# rl2_of_cba4_RL2_OF_CBA4_25000000h register map
Vendor: Texas Instruments
Peripheral module from a debugger description file (folder AM275x).
Registers are 32-bit, read-write, reset 0x0 unless marked. A register's access mark holds for its fields unless they carry their own. Offsets are as the file gives them; lines under a group give offsets from that group; [hi:lo] are bit positions; {n}, {i} and the like mark numbered series; 'fields as' and 'values as' point back to an identical list; <NAME> marks a mode.

## rl2_of_cba4
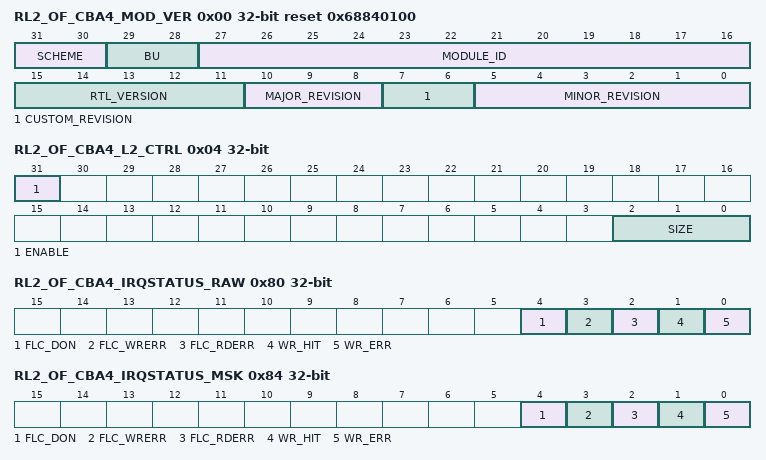
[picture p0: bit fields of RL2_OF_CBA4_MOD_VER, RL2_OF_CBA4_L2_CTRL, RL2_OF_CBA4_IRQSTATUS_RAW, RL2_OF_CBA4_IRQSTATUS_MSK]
0x00 RL2_OF_CBA4_MOD_VER ro reset 0x68840100 — The Module and Version Register identifies the module identifier and revision of the RL2 module.
  [31:30] SCHEME — Module Scheme
  [29:28] BU — Module Business Unit
  [27:16] MODULE_ID — RL2 module ID.
  [15:11] RTL_VERSION
  [10:8] MAJOR_REVISION
  [7:6] CUSTOM_REVISION
  [5:0] MINOR_REVISION
0x04 RL2_OF_CBA4_L2_CTRL — The control register defines the size of the remote cache data storage memory to use and whether the L2 is enabled.
  [31] ENABLE — The ~ienable field determines whether the L2 is enabled or not. Setting the enable from a 0 to 1 restarts the cache 0: Disabled 1: Enabled
  [2:0] SIZE — The ~isize field determines the size of the remote cache data storage memory that is currently active. This field can be change dynamically, but will cause the entire cache to be invalidated when inflight transactions have completed. Changing the ~isize while ~ienable is already a '1' will restart the cache. 0: 8KB 1: 16KB 2: 32KB 3: 64KB 4: 128KB 5: 256KB (Dual Mode) Note: Setting this field to an invalid value will result in the field being set to '0'. The remote address range registers must be setup correctly to ensure it has sufficient memory for the selected size.
0x08 RL2_OF_CBA4_L2_STS ro — The Status register displays the state of the RL2 module
  [31] OK_TO_GO — The ~iok_to_go status bit indicates the Tag/LRU Ram has been initialized and the cache is in an operable state.
0x10 RL2_OF_CBA4_L2_LO_LSW — The L2 Low address Least Significant word defines the least significant portion of the low cache address. The RL2 cache can cache a range of 1 to 16MB of cache as defined by L2_LO>=CachedRange<=L2_HI. This register is write protected when ~ienable is set.
  [31:11] ADDRESS_LO_LSW — The ~iaddress_lo_lsw defines the L2 low address[31:11] for the RL2 to cache. The remaining bits 10:0 are assumed to be zero.
0x14 RL2_OF_CBA4_L2_LO_MSW — The L2 Low address Most Significant word defines the most significant portion of the low cache address. The RL2 cache can cache a range of 1 to 16MB of cache as defined by L2_LO>=CachedRange<=L2_HI. This register is write protected when ~ienable is set.
  [15:0] ADDRESS_LO_MSW — The ~iaddress_lo_msw defines the L2 low address[ 47:32] for the RL2 to cache.
0x18 RL2_OF_CBA4_L2_HI — The L2 High address Least Significant word defines the least significant portion of the high cache address. The RL2 cache can cache a range of 1 to 16MB of cache as defined by L2_LO>=CachedRange<=L2_HI. This register is write protected when ~ienable is set.
  [31:11] ADDRESS_HI_LSW — The ~iaddress_hi_lsw defines the high address[31:11] for the RL2 to cache. The remaining bits 10:0 are assumed to be ones.
0x1C RL2_OF_CBA4_L2_HI_MSW — The L2 Hi address Most Significant word defines the most significant portion of the high cache address. The RL2 cache can cache a range of 1 to 16MB of cache as defined by L2_LO>=CachedRange<=L2_HI. This register is write protected when ~ienable is set.
  [15:0] ADDRESS_HI_MSW — The ~iaddress_lo_msw defines the L2 hi address[ 47:32] for the RL2 to cache.
0x20 RL2_OF_CBA4_REM_ADR — The REMote 'n' Address Least Significant word defines the least significant portion of the Remote address for remote cache data storage memory 0. The RL2 cache use up to three remote cache data storage memory ranges to place the L2 data within. The length of these ranges must be greater or equal to the size specified. This register is write protected when ~ienable is set.
  [31:11] ADR_LSW — The ~irem0_adr_lsw defines the LSW of the remote cache data storage memory address[31:11] range 'n' for the RL2 to use for the cache. The remaining bits 10:0 are assumed to be zero.
0x24 RL2_OF_CBA4_REM_ADR_MSW — The REMote 'n' Address Most Significant word defines the Most significant portion of the Remote address for remote cache data storage memory 0. The RL2 cache use up to three remote cache data storage memory ranges to place the L2 data within. The length of these ranges must be greater or equal to the size specified. This register is write protected when ~ienable is set.
  [15:0] ADR_MSW — The ~irem0_adr_lsw defines the LSW of the remote cache data storage memory address[47:32] range 'n' for the RL2 to use for the cache.
0x28 RL2_OF_CBA4_REM_LEN — The Remote 'n' length defines the amount of remote cache data storage memory in 64 byte aligned quanta used starting from the REMote 'n' Address. The RL2 consumes remote cache data storage memory ranges in numeric order. Range 0 is consumed prior to range 1, etc. This register is write protected when ~ienable is set.
  [18:6] LEN — The ~irem0_len field specifies the length of the remote cache data storage memory 'n' to use for the RL2 cache in 64 byte quanta, That is the number of bytes specified in the remote cache data storage memory range 'n' is (~irem0_len X 64). Note: Any value greater than 4096 assumes 4096
0x78 RL2_OF_CBA4_L2HC — The L2 HIT Counter register holds the number of L2 Hits to the Remote data storage memory.
  [31:0] HIT — The ~ihit Counts the number of hits to the L2 cache. Writing to this register will set the value written or restarting the cache will clear its contents. This field does not roll over, it will stop counting at all ones.
0x7C RL2_OF_CBA4_L2MC — The L2 MISS Counter register holds the number of L2 Misses to the Remote data storage memory.
  [31:0] MISS — The ~imiss Counts the number of misses to the L2 cache. Writing to this register will set the value written or restarting the cache will clear its contents. This field does not roll over, it will stop counting at all ones.
0x80 RL2_OF_CBA4_IRQSTATUS_RAW access not given — The Interrupt Raw Status Register holds the raw status of the FLC/RL2 status/error interrupts.
  [4] FLC_DON — The ~iflc_don bit indicates a FLC has completed the transfer to the FLC range. Write 1 to set the ~iflc_don status for diagnostic purposes. Writing a 0 has no effect. (access R/W1TS)
  [3] FLC_WRERR — The ~iflc_wrerr bit indicates a write error from FLC remote range has occurred and the FLC is logically disabled while this bit is a '1'. Write 1 to set the ~iflc_wrerr status for diagnostic purposes. Writing a 0 has no effect. (access R/W1TS)
  [2] FLC_RDERR — The ~iflc_rderr bit indicates a read error from FLC range has occurred and the FLC is logically disabled while this bit is a '1'. Write 1 to set the ~iflc_rderr status for diagnostic purposes. Writing a 0 has no effect. (access R/W1TS)
  [1] WR_HIT — The ~iwr_hit bit indicates a write to the cacheable range has occurred potentially causing a coherency issue and the RL2 is logically disabled while this bit is a '1'. Write 1 to set the ~iwr_hit status for diagnostic purposes. Writing a 0 has no effect. (access R/W1TS)
  [0] WR_ERR — The ~iwr_err bit indicates a write error has occurred to the remote cache data storage memory and the RL2 is logically disabled while this bit is a '1'. Write 1 to set the ~iwr_err status for diagnostic purposes. Writing a 0 has no effect. (access R/W1TS)
0x84 RL2_OF_CBA4_IRQSTATUS_MSK access not given — The Interrupt Masked Status Register holds the masked status for the FLC/RL2 status/error interrupts. Writing to this register will EOI the interrupt, that is if another interrupt is pending, a new pulse interrupt will be generated.
  [4] FLC_DON — The ~iflc_don bit indicates a FLC has completed the transfer to the FLC range. Write 1 to clear the ~iflc_don status after interrupt has been serviced (raw status gets cleared, i.e. even if not enabled). Writing a 0 has no effect to this field. (access R/W1TC)
  [3] FLC_WRERR — The ~iflc_wrerr bit indicates a write error from FLC range has occurred and the FLC is logically disabled while this bit is a '1'. Write 1 to clear the ~iflc_wrerr status after interrupt has been serviced (raw status gets cleared, i.e. even if not enabled). Writing a 0 has no effect to this field. (access R/W1TC)
  [2] FLC_RDERR — The ~iflc_rderr bit indicates a read error from FLC range has occurred and the FLC is logically disabled while this bit is a '1'. Write 1 to clear the ~iflc_rderr status after interrupt has been serviced (raw status gets cleared, i.e. even if not enabled). Writing a 0 has no effect to this field. (access R/W1TC)
  [1] WR_HIT — The ~iwr_hit bit indicates a write to the cacheable range has occurred potentially causing a coherency issue and the RL2 is logically disabled while this bit is a '1'. Write 1 to clear the ~iwr_hit status after interrupt has been serviced (raw status gets cleared, i.e. even if not enabled). Writing a 0 has no effect to this field. (access R/W1TC)
  [0] WR_ERR — The ~iwr_err bit indicates a write error has occurred to the remote cache data storage memory and the RL2 is logically disabled while this bit is a '1'. Write 1 to clear the ~iwr_err status after interrupt has been serviced (raw status gets cleared, i.e. even if not enabled). Writing a 0 has no effect to this field. (access R/W1TC)
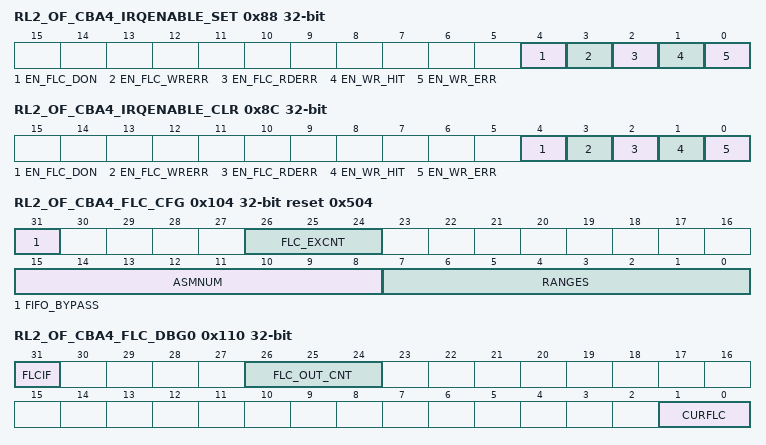
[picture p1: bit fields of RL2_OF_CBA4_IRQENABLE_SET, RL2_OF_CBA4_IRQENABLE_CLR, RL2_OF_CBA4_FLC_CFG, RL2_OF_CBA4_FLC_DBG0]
0x88 RL2_OF_CBA4_IRQENABLE_SET access not given — The Interrupt Enable Set Register holds the interrupt enable status of the FLC/RL2 status/error interrupts.
  [4] EN_FLC_DON — Interrupt Enable Set for ~ien_flc_don status bit. Writing a 1 will enable the interrupt, and set this bit as well as the corresponding Interrupt Enable Clear Register. Writing a 0 has no effect. (access R/W1TS)
  [3] EN_FLC_WRERR — Interrupt Enable Set for ~ien_flc_wrerr error bit. Writing a 1 will enable the interrupt, and set this bit as well as the corresponding Interrupt Enable Clear Register. Writing a 0 has no effect. (access R/W1TS)
  [2] EN_FLC_RDERR — Interrupt Enable Set for ~ien_flc_rderr error bit. Writing a 1 will enable the interrupt, and set this bit as well as the corresponding Interrupt Enable Clear Register. Writing a 0 has no effect. (access R/W1TS)
  [1] EN_WR_HIT — Interrupt Enable Set for ~iwr_hit error bit. Writing a 1 will enable the interrupt, and set this bit as well as the corresponding Interrupt Enable Clear Register. Writing a 0 has no effect. (access R/W1TS)
  [0] EN_WR_ERR — Interrupt Enable Set for ~iwr_err error bit. Writing a 1 will enable the interrupt, and set this bit as well as the corresponding Interrupt Enable Clear Register. Writing a 0 has no effect. (access R/W1TS)
0x8C RL2_OF_CBA4_IRQENABLE_CLR access not given — The Interrupt Enable Clear Register holds the interrupt enable status of the FLC/RL2 status/error interrupts.
  [4] EN_FLC_DON — Interrupt Enable Clear for ~iflc_don status bit. Writing a 1 will disable the interrupt, and clear this bit as well as the corresponding Interrupt Enable Set Register. Writing a 0 has no effect. (access R/W1TC)
  [3] EN_FLC_WRERR — Interrupt Enable Clear for ~iflc_wrerr error bit. Writing a 1 will disable the interrupt, and clear this bit as well as the corresponding Interrupt Enable Set Register. Writing a 0 has no effect. (access R/W1TC)
  [2] EN_FLC_RDERR — Interrupt Enable Clear for ~iflc_rderr error bit. Writing a 1 will disable the interrupt, and clear this bit as well as the corresponding Interrupt Enable Set Register. Writing a 0 has no effect. (access R/W1TC)
  [1] EN_WR_HIT — Interrupt Enable Clear for ~iwr_hit error bit. Writing a 1 will disable the interrupt, and clear this bit as well as the corresponding Interrupt Enable Set Register. Writing a 0 has no effect. (access R/W1TC)
  [0] EN_WR_ERR — Interrupt Enable Clear for ~iwr_err error bit. Writing a 1 will disable the interrupt, and clear this bit as well as the corresponding Interrupt Enable Set Register. Writing a 0 has no effect. (access R/W1TC)
0x104 RL2_OF_CBA4_FLC_CFG access per field reset 0x504 — The FLC Config Register contains the configuration values for the FLC.
  [31] FIFO_BYPASS rw — Setting this bit will cause the write to remote memory for a cache miss or FLC return to forces stalls on the read returns if any other data phase for a cache miss or FLC return is received. This can cause stalls on the write to force stalls on the read.
  [26:24] FLC_EXCNT rw — The number of extra requests the FLC can send. The maximum value is 4 anything greater will default to 4. This value + 1 is the number of Reassembly Buffers used for FLC so if cache misses needed to be supported this value should be set to 4 or lower. The number of cache misses that will be allowed to be outstanding while FLC is running will be 5 - (FLC_EXCNT + 1).
  [15:8] ASMNUM ro — Number of Reassembly Buffer supported
  [7:0] RANGES ro — Number of FLC ranges supported
0x108 RL2_OF_CBA4_FLC_STS ro — The FLC Status Register will indicate the state of the FLC completion.
  [3:0] CPYCMP — The ~icpycmp indicates which FLC range is complete. Each bit index indicates the FLC range is complete.
0x110 RL2_OF_CBA4_FLC_DBG0 ro — The FLC Debug 0 Register holds the debug state of the FLC.
  [31] FLCIF — The ~iflcif indicates a FLC operation is in flight.
  [26:24] FLC_OUT_CNT — The number of read requests the FLC operation has in flight.
  [1:0] CURFLC — The ~icurflc indicates which FLC range is in flight.
0x114 RL2_OF_CBA4_FLC_DBG1 ro — The FLC Debug 1 Register holds the debug address of the FLC.
  [31:0] FLCADR_LO — The ~iflcadr indicates the next FLC address to be processed if still in flight. That is all addresses less than this address have been transferred. This address is used for FLC hit when the particular FLC range is in flight. That is FLC_LO?>=FLCrange<~iflc_dbg1.flcadr would result in a hit. This address will match the last FLC transferred FLC_HI? when no FLC ranges are in flight.
0x118 RL2_OF_CBA4_FLC_DBG2 ro — The FLC Debug 2 Register holds the upper portion of the debug address of the FLC.
  [15:0] FLCADR_HI — The ~iflcadr indicates the next FLC address to be processed if still in flight. That is all addresses less than this address have been transferred. This address is used for FLC hit when the particular FLC range is in flight. That is FLC_LO?>=FLCrange<~iflc_dbg1.flcadr would result in a hit. This address will match the last FLC transferred FLC_HI? when no FLC ranges are in flight.
0x120 RL2_OF_CBA4_FLC_LO_j — The FLC Low 'n' address defines the FLC lo address for FLC range 0. The FLC range is defined by FLC_LO0>=FLCrange<FLC_HI0. This register is write protected when ~ifenable0 is set.
  [31:12] ADR_LO_LSW — The ~iadr0_lo defines the FLC low address[31:12] for the FLC to copy. The remaining bits 11:0 are assumed to be zero.
0x124 RL2_OF_CBA4_FLC_LO_MSW_j — The FLC Low 'n' address defines the FLC lo address for FLC range 0. The FLC range is defined by FLC_LO0>=FLCrange<FLC_HI0. This register is write protected when ~ifenable0 is set.
  [15:0] ADR_LO_MSW — The ~iadr0_lo defines the FLC low address[47:32] for the FLC to copy.
0x128 RL2_OF_CBA4_FLC_HI_j — The FLC High 'n' address defines the FLC high address for FLC range 0. The FLC range is defined by FLC_LO0>=FLCrange<FLC_HI0. This register is write protected when ~ifenable0 is set.
  [31:12] ADR_HI_LSW — The ~iadr0_hi defines the FLC high address[31:12] for the FLC to copy. The remaining bits 11:0 are assumed to be ones.
0x12C RL2_OF_CBA4_FLC_HI_MSW_j — The FLC High 'n' address defines the FLC high address for FLC range 0. The FLC range is defined by FLC_LO0>=FLCrange<FLC_HI0. This register is write protected when ~ifenable0 is set.
  [15:0] ADR_HI_MSW — The ~iadr0_lo defines the FLC Hi address[47:32] for the FLC to copy.
0x130 RL2_OF_CBA4_FLC_RA_j — The FLC Remote Address 'n' specifies the SRAM location base address the FLC will copy slow Flash data to the SRAM. That is the SRAM is acting like a block cache for a slow device.
  [31:12] RADR_LSW — The ~iradr0 specifies the remote SRAM address for FLC data to be copied. The SRAM must be large enough for the specified range.
0x134 RL2_OF_CBA4_FLC_RA_MSW_j — The FLC Remote Address 'n' specifies the SRAM location base address the FLC will copy slow Flash data to the SRAM. That is the SRAM is acting like a block cache for a slow device.
  [15:0] RADR_MSW — The ~iradr0 specifies the remote SRAM address for FLC data to be copied. This defines FLC0_RA address47:32] The SRAM must be large enough for the specified range.
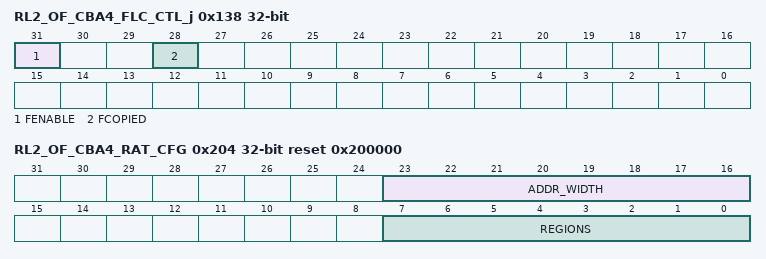
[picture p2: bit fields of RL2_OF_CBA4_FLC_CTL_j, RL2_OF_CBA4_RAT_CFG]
0x138 RL2_OF_CBA4_FLC_CTL_j — The FLC Control 'n' enables the given range FLC_LO0>=FLCrange<FLC_HI0 to be copied to the FLC_RA0 SRAM memory.
  [31] FENABLE — The ~ifenable0 enables the FLC_LO0>=FLCrange<FLC_HI0 to be copied. if the ~ifenable0 is set to zero, the range is disabled and commands forwarded directly without change.
  [28] FCOPIED — The ~ifcopied0 bit indicates the FLC range has already been copied to the ~iradr0 address so a transfer is not required. Setting this bit at the same cycle or prior to setting the ~ifenable will prevent the FLC transfer but enable the mapping.
0x204 RL2_OF_CBA4_RAT_CFG ro reset 0x200000 — The RAT Config Register contains the configuration values for the RAT.
  [23:16] ADDR_WIDTH — Number of address bits
  [7:0] REGIONS — Number of regions
0x300 RL2_OF_CBA4_TRK0_LO — The Track Low 0 address defines the Track lo address for Track range 0. The Track range is defined by TRK_LO0>=TRKrange<TRK_HI0, if a read is in this range then while it is outstanding the trk0_active pin will be asserted. This register is write protected when ~trk_ifenable0 is set.
  [31:12] TRK0_ADR_LO_LSW — The ~trk0_adr_lo defines the TRK low address[31:12] for the Tracking function. The remaining bits 11:0 are assumed to be zero.
0x304 RL2_OF_CBA4_TRK0_LO_MSW — The Track Low 0 address defines the Track lo address for Track range 0. The Track range is defined by TRK_LO0>=TRKrange<TRK_HI0, if a read is in this range then while it is outstanding the trk0_active pin will be asserted. This register is write protected when ~trk_ifenable0 is set.
  [15:0] TRK0_ADR_LO_MSW — The ~iadr0_lo defines the TRK low address[47:32] for the Tracking Function
0x308 RL2_OF_CBA4_TRK0_HI — The Track High 0 address defines the Track High address for Track range 0. The Track range is defined by TRK_LO0>=TRKrange<TRK_HI0, if a read is in this range then while it is outstanding the trk0_active pin will be asserted. This register is write protected when ~trk_ifenable0 is set.
  [31:12] TRK0_ADR_HI_LSW — The ~trk0_hi defines the TRK low address[31:12] for the Tracking function. The remaining bits 11:0 are assumed to be zero.
0x30C RL2_OF_CBA4_TRK0_HI_MSW — The Track Hi 0 address defines the Track hi address for Track range 0. The Track range is defined by TRK_LO0>=TRKrange<TRK_HI0, if a read is in this range then while it is outstanding the trk0_active pin will be asserted. This register is write protected when ~trk_ifenable0 is set.
  [15:0] TRK0_ADR_HI_MSW — The ~iadr0_lo defines the TRK low address[47:32] for the Tracking Function
0x310 RL2_OF_CBA4_TRK0_CTL — The Track Control 0 enables the given range TRK_LO0>=TRKrange<TRK_HI0 to generate the output on trk0_active pin.
  [31] TRK0_FENABLE — The ~ifenable0 enables the TRL_LO0>=TRKrange<TRK_HI0 to assert the output pin trk0_active. if the ~ifenable0 is set to zero, the range is disabled and the output will remain low.
